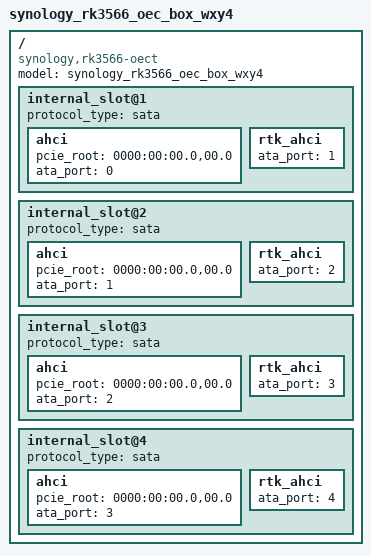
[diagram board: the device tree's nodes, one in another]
// SPDX-License-Identifier: (GPL-2.0+ OR MIT)
/*
 * DSM wrapper for the RK3566 OEC BOX WXY4 board.
 *
 * Keep the board hardware in rk3566-oec-box-wxy4.dtsi so the same base
 * description can be reused outside DSM.
 */

/dts-v1/;

#include "rk3566-oec-box.dtsi"

/ {
	model = "synology_rk3566_oec_box_wxy4";
	compatible = "synology,rk3566-oect", "rockchip,rk3566";

	internal_slot@1 {
		protocol_type = "sata";

		ahci {
			pcie_root = "0000:00:00.0,00.0";
			ata_port = <0>;
		};

		rtk_ahci {
			#address-cells = <1>;
			ata_port = <1>;
		};
	};

	internal_slot@2 {
		protocol_type = "sata";

		ahci {
			pcie_root = "0000:00:00.0,00.0";
			ata_port = <1>;
		};

		rtk_ahci {
			ata_port = <2>;
		};
	};

	internal_slot@3 {
		protocol_type = "sata";

		ahci {
			pcie_root = "0000:00:00.0,00.0";
			ata_port = <2>;
		};

		rtk_ahci {
			ata_port = <3>;
		};
	};

	internal_slot@4 {
		protocol_type = "sata";

		ahci {
			pcie_root = "0000:00:00.0,00.0";
			ata_port = <3>;
		};

		rtk_ahci {
			ata_port = <4>;
		};
	};
};
